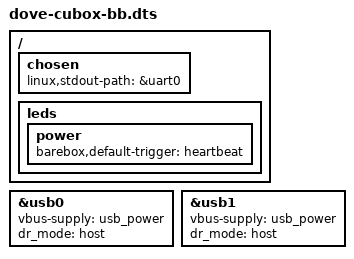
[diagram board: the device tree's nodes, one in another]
/*
 * Barebox specific DT overlay for SolidRun CuBox
 *   Sebastian Hesselbarth <sebastian.hesselbarth@gmail.com>
 */

#include "arm/dove-cubox.dts"
#include "dove-usb.dtsi"

/ {
	chosen {
		linux,stdout-path = &uart0;
	};

	leds {
		power {
			barebox,default-trigger = "heartbeat";
		};
	};
};

&usb0 {
	vbus-supply = <&usb_power>;
	dr_mode = "host";
	status = "okay";
};

&usb1 {
	vbus-supply = <&usb_power>;
	dr_mode = "host";
	status = "okay";
};
